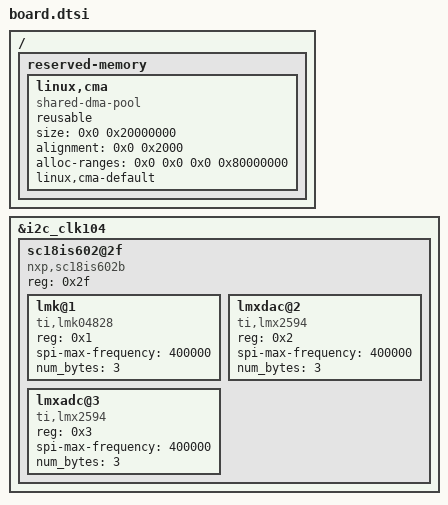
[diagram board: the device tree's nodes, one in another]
/* ZCU208 board-specific device-tree nodes (appended to the SDT base dts).
 * CLK104 clocking (LMK04828 + dual LMX2594) hangs off i2c_clk104, which the
 * SDT base dts already exposes at /axi/i2c@ff030000/i2c-mux@74/i2c@5. */

/ {
	reserved-memory {
		#address-cells = <2>;
		#size-cells = <2>;
		ranges;
		linux,cma {
			compatible = "shared-dma-pool";
			reusable;
			size = <0x0 0x20000000>;
			alignment = <0x0 0x2000>;
			/* Pin the cma pool to the low 2 GB DDR bank so the FPGA-manager
			 * bitstream DMA gets DMA-reachable contiguous memory. */
			alloc-ranges = <0x0 0x0 0x0 0x80000000>;
			linux,cma-default;
		};
	};
};

&i2c_clk104 {
	sc18is602@2f {
		compatible = "nxp,sc18is602b";
		reg = <0x2f>;
		#address-cells = <0x1>;
		#size-cells = <0x0>;
		lmk@1 {
			compatible = "ti,lmk04828";
			reg = <0x1>;
			spi-max-frequency = <400000>;
			num_bytes = <3>;
		};
		lmxdac@2 {
			compatible = "ti,lmx2594";
			reg = <0x2>;
			spi-max-frequency = <400000>;
			num_bytes = <3>;
		};
		lmxadc@3 {
			compatible = "ti,lmx2594";
			reg = <0x3>;
			spi-max-frequency = <400000>;
			num_bytes = <3>;
		};
	};
};
